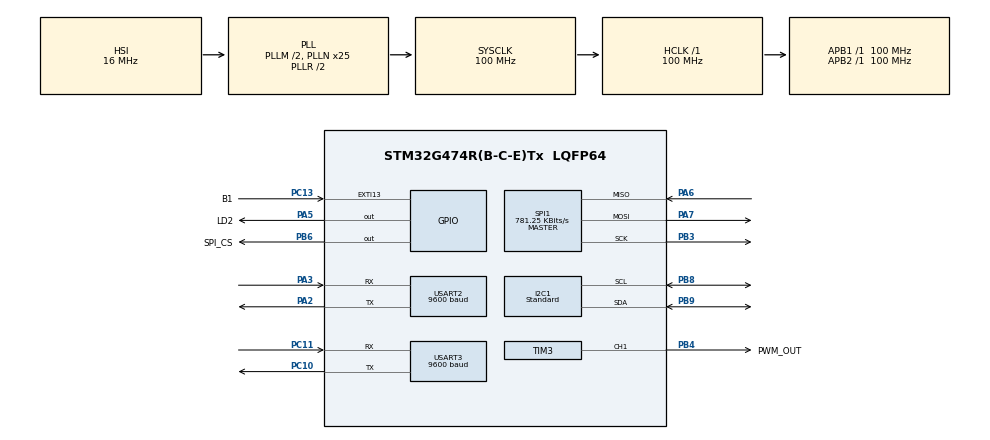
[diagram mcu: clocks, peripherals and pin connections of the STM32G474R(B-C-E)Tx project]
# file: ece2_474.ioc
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I2C1.AddressingMode=I2C_ADDRESSINGMODE_7BIT
I2C1.Analog_Filter=I2C_ANALOGFILTER_ENABLE
I2C1.CustomTiming=Disabled
I2C1.DualAddressMode=I2C_DUALADDRESS_DISABLE
I2C1.GeneralCallMode=I2C_GENERALCALL_DISABLE
I2C1.I2C_Coeff_DF=0
I2C1.I2C_Fall_Time=10
I2C1.I2C_Rise_Time=100
I2C1.I2C_Speed_Mode=I2C_Standard
I2C1.NoStretchMode=I2C_NOSTRETCH_DISABLE
I2C1.OwnAddress=0
I2C1.Speed=100
Mcu.Family=STM32G4
Mcu.Name=STM32G474R(B-C-E)Tx
Mcu.Package=LQFP64
NVIC.EXTI15_10_IRQn=true\:7\:0\:false\:false\:true\:true\:true\:true
NVIC.PriorityGroup=NVIC_PRIORITYGROUP_4
NVIC.TIM6_DAC_IRQn=true\:4\:0\:false\:false\:true\:true\:true\:true
NVIC.USART2_IRQn=true\:6\:0\:false\:false\:true\:true\:true\:true
NVIC.USART3_IRQn=true\:5\:0\:false\:false\:true\:true\:true\:true
PA13.Mode=Serial_Wire
PA13.Signal=SYS_JTMS-SWDIO
PA14.Mode=Serial_Wire
PA14.Signal=SYS_JTCK-SWCLK
PA2.Mode=Asynchronous
PA2.Signal=USART2_TX
PA3.Mode=Asynchronous
PA3.Signal=USART2_RX
PA5.GPIO_Label=LD2
PA5.PinState=GPIO_PIN_RESET
PA5.Signal=GPIO_Output
PA6.Mode=Full_Duplex_Master
PA6.Signal=SPI1_MISO
PA7.Mode=Full_Duplex_Master
PA7.Signal=SPI1_MOSI
PB3.Mode=Full_Duplex_Master
PB3.Signal=SPI1_SCK
PB4.GPIO_Label=PWM_OUT
PB4.Signal=S_TIM3_CH1
PB6.GPIO_Label=SPI_CS
PB6.PinState=GPIO_PIN_SET
PB6.Signal=GPIO_Output
PB8-BOOT0.Mode=I2C
PB8-BOOT0.Signal=I2C1_SCL
PB9.Mode=I2C
PB9.Signal=I2C1_SDA
PC10.Mode=Asynchronous
PC10.Signal=USART3_TX
PC11.Mode=Asynchronous
PC11.Signal=USART3_RX
PC13.GPIO_Label=B1
PC13.GPIO_ModeDefaultEXTI=GPIO_MODE_IT_RISING
PC13.GPIO_PuPd=GPIO_NOPULL
PC13.Signal=GPXTI13
ProjectManager.HeapSize=0x200
ProjectManager.StackSize=0x400
ProjectManager.TargetToolchain=CMake
RCC.ADC12Freq_Value=100000000
RCC.ADC345Freq_Value=100000000
RCC.AHBFreq_Value=100000000
RCC.APB1Freq_Value=100000000
RCC.APB1TimFreq_Value=100000000
RCC.APB2Freq_Value=100000000
RCC.APB2TimFreq_Value=100000000
RCC.CortexFreq_Value=100000000
RCC.EXTERNAL_CLOCK_VALUE=12288000
RCC.HCLKFreq_Value=100000000
RCC.HSE_VALUE=8000000
RCC.HSI48_VALUE=48000000
RCC.HSI_VALUE=16000000
RCC.LSE_VALUE=32768
RCC.PLLM=RCC_PLLM_DIV2
RCC.PLLN=25
RCC.SYSCLKFreq_VALUE=100000000
RCC.SYSCLKSource=RCC_SYSCLKSOURCE_PLLCLK
RCC.USBFreq_Value=100000000
RCC.VCOOutputFreq_Value=200000000
SH.S_TIM3_CH1.0=TIM3_CH1,PWM Generation1 CH1
SPI1.BaudRatePrescaler=SPI_BAUDRATEPRESCALER_128
SPI1.CLKPhase=SPI_PHASE_1EDGE
SPI1.CLKPolarity=SPI_POLARITY_LOW
SPI1.CRCCalculation=SPI_CRCCALCULATION_DISABLE
SPI1.CalculateBaudRate=781.25 KBits/s
SPI1.DataSize=SPI_DATASIZE_8BIT
SPI1.Direction=SPI_DIRECTION_2LINES
SPI1.FirstBit=SPI_FIRSTBIT_MSB
SPI1.Mode=SPI_MODE_MASTER
SPI1.NSS=SPI_NSS_SOFT
SPI1.NSSPMode=SPI_NSS_PULSE_DISABLE
SPI1.TIMode=SPI_TIMODE_DISABLE
SPI1.VirtualType=VM_MASTER
TIM3.AutoReloadPreload=TIM_AUTORELOAD_PRELOAD_DISABLE
TIM3.Channel-PWM\ Generation1\ CH1=TIM_CHANNEL_1
TIM3.ClockDivision=TIM_CLOCKDIVISION_DIV1
TIM3.CounterMode=TIM_COUNTERMODE_UP
TIM3.Dithering=Disable
TIM3.OCFastMode_PWM-PWM\ Generation1\ CH1=TIM_OCFAST_DISABLE
TIM3.OCMode_PWM-PWM\ Generation1\ CH1=TIM_OCMODE_PWM1
TIM3.OCPolarity_1=TIM_OCPOLARITY_HIGH
TIM3.PeriodNoDither=999
TIM3.Prescaler=99
TIM3.PulseNoDither_1=500
TIM3.TIM_MasterOutputTrigger=TIM_TRGO_RESET
TIM3.TIM_MasterSlaveMode=TIM_MASTERSLAVEMODE_DISABLE
TIM6.AutoReloadPreload=TIM_AUTORELOAD_PRELOAD_DISABLE
TIM6.CounterMode=TIM_COUNTERMODE_UP
TIM6.Dithering=Disable
TIM6.PeriodNoDither=999
TIM6.Prescaler=9999
TIM6.TIM_MasterOutputTrigger=TIM_TRGO_RESET
USART2.BaudRate=9600
USART2.Mode=MODE_TX_RX
USART2.OverSampling=UART_OVERSAMPLING_16
USART2.Parity=PARITY_NONE
USART2.StopBits=STOPBITS_1
USART2.VirtualMode-Asynchronous=VM_ASYNC
USART2.WordLength=WORDLENGTH_8B
USART3.BaudRate=9600
USART3.Mode=MODE_TX_RX
USART3.OverSampling=UART_OVERSAMPLING_16
USART3.Parity=PARITY_NONE
USART3.StopBits=STOPBITS_1
USART3.VirtualMode-Asynchronous=VM_ASYNC
USART3.WordLength=WORDLENGTH_8B
VP_SYS_VS_DBSignals.Mode=DisableDeadBatterySignals
VP_TIM3_VS_ClockSourceINT.Mode=Internal
VP_TIM6_VS_ClockSourceINT.Mode=Enable_Timer
board=NUCLEO-G474RE

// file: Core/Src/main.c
/* USER CODE BEGIN Header */
/**
  ******************************************************************************
  * @file           : main.c
  * @brief          : Main program body
  ******************************************************************************
  * @attention
  *
  * Copyright (c) 2026 STMicroelectronics.
  * All rights reserved.
  *
  * This software is licensed under terms that can be found in the LICENSE file
  * in the root directory of this software component.
  * If no LICENSE file comes with this software, it is provided AS-IS.
  *
  ******************************************************************************
  */
/* USER CODE END Header */
#include "main.h"

/* USER CODE BEGIN Includes */
#include "ece2_474.h"
/* USER CODE END Includes */

I2C_HandleTypeDef hi2c1;

SPI_HandleTypeDef hspi1;

TIM_HandleTypeDef htim3;
TIM_HandleTypeDef htim6;

UART_HandleTypeDef huart2;
UART_HandleTypeDef huart3;

void SystemClock_Config(void);
static void MX_GPIO_Init(void);
static void MX_USART2_UART_Init(void);
static void MX_SPI1_Init(void);
static void MX_I2C1_Init(void);
static void MX_TIM6_Init(void);
static void MX_TIM3_Init(void);
static void MX_USART3_UART_Init(void);

int main(void)
{

  /* MCU Configuration--------------------------------------------------------*/

  /* Reset of all peripherals, Initializes the Flash interface and the Systick. */
  HAL_Init();

  /* Configure the system clock */
  SystemClock_Config();

  /* Initialize all configured peripherals */
  MX_GPIO_Init();
  MX_USART2_UART_Init();
  MX_SPI1_Init();
  MX_I2C1_Init();
  MX_TIM6_Init();
  MX_TIM3_Init();
  MX_USART3_UART_Init();
  /* USER CODE BEGIN 2 */
  printf("Hello, World!\n");
  /* USER CODE END 2 */

  /* Infinite loop */
  while (1)
  {
    /* USER CODE BEGIN 3 */
    polling_routine();
  }

  /* USER CODE END 3 */
}

void SystemClock_Config(void)
{
  RCC_OscInitTypeDef RCC_OscInitStruct = {0};
  RCC_ClkInitTypeDef RCC_ClkInitStruct = {0};

  /** Configure the main internal regulator output voltage
  */
  HAL_PWREx_ControlVoltageScaling(PWR_REGULATOR_VOLTAGE_SCALE1);

  /** Initializes the RCC Oscillators according to the specified parameters
  * in the RCC_OscInitTypeDef structure.
  */
  RCC_OscInitStruct.OscillatorType = RCC_OSCILLATORTYPE_HSI;
  RCC_OscInitStruct.HSIState = RCC_HSI_ON;
  RCC_OscInitStruct.HSICalibrationValue = RCC_HSICALIBRATION_DEFAULT;
  RCC_OscInitStruct.PLL.PLLState = RCC_PLL_ON;
  RCC_OscInitStruct.PLL.PLLSource = RCC_PLLSOURCE_HSI;
  RCC_OscInitStruct.PLL.PLLM = RCC_PLLM_DIV2;
  RCC_OscInitStruct.PLL.PLLN = 25;
  RCC_OscInitStruct.PLL.PLLP = RCC_PLLP_DIV2;
  RCC_OscInitStruct.PLL.PLLQ = RCC_PLLQ_DIV2;
  RCC_OscInitStruct.PLL.PLLR = RCC_PLLR_DIV2;
  if (HAL_RCC_OscConfig(&RCC_OscInitStruct) != HAL_OK)
  {
    Error_Handler();
  }

  /** Initializes the CPU, AHB and APB buses clocks
  */
  RCC_ClkInitStruct.ClockType = RCC_CLOCKTYPE_HCLK|RCC_CLOCKTYPE_SYSCLK
                              |RCC_CLOCKTYPE_PCLK1|RCC_CLOCKTYPE_PCLK2;
  RCC_ClkInitStruct.SYSCLKSource = RCC_SYSCLKSOURCE_PLLCLK;
  RCC_ClkInitStruct.AHBCLKDivider = RCC_SYSCLK_DIV1;
  RCC_ClkInitStruct.APB1CLKDivider = RCC_HCLK_DIV1;
  RCC_ClkInitStruct.APB2CLKDivider = RCC_HCLK_DIV1;

  if (HAL_RCC_ClockConfig(&RCC_ClkInitStruct, FLASH_LATENCY_3) != HAL_OK)
  {
    Error_Handler();
  }
}

static void MX_I2C1_Init(void)
{

  hi2c1.Instance = I2C1;
  hi2c1.Init.Timing = 0x00303D5B;
  hi2c1.Init.OwnAddress1 = 0;
  hi2c1.Init.AddressingMode = I2C_ADDRESSINGMODE_7BIT;
  hi2c1.Init.DualAddressMode = I2C_DUALADDRESS_DISABLE;
  hi2c1.Init.OwnAddress2 = 0;
  hi2c1.Init.OwnAddress2Masks = I2C_OA2_NOMASK;
  hi2c1.Init.GeneralCallMode = I2C_GENERALCALL_DISABLE;
  hi2c1.Init.NoStretchMode = I2C_NOSTRETCH_DISABLE;
  if (HAL_I2C_Init(&hi2c1) != HAL_OK)
  {
    Error_Handler();
  }

  /** Configure Analogue filter
  */
  if (HAL_I2CEx_ConfigAnalogFilter(&hi2c1, I2C_ANALOGFILTER_ENABLE) != HAL_OK)
  {
    Error_Handler();
  }

  /** Configure Digital filter
  */
  if (HAL_I2CEx_ConfigDigitalFilter(&hi2c1, 0) != HAL_OK)
  {
    Error_Handler();
  }

}

static void MX_SPI1_Init(void)
{

  /* SPI1 parameter configuration*/
  hspi1.Instance = SPI1;
  hspi1.Init.Mode = SPI_MODE_MASTER;
  hspi1.Init.Direction = SPI_DIRECTION_2LINES;
  hspi1.Init.DataSize = SPI_DATASIZE_8BIT;
  hspi1.Init.CLKPolarity = SPI_POLARITY_LOW;
  hspi1.Init.CLKPhase = SPI_PHASE_1EDGE;
  hspi1.Init.NSS = SPI_NSS_SOFT;
  hspi1.Init.BaudRatePrescaler = SPI_BAUDRATEPRESCALER_128;
  hspi1.Init.FirstBit = SPI_FIRSTBIT_MSB;
  hspi1.Init.TIMode = SPI_TIMODE_DISABLE;
  hspi1.Init.CRCCalculation = SPI_CRCCALCULATION_DISABLE;
  hspi1.Init.CRCPolynomial = 7;
  hspi1.Init.CRCLength = SPI_CRC_LENGTH_DATASIZE;
  hspi1.Init.NSSPMode = SPI_NSS_PULSE_DISABLE;
  if (HAL_SPI_Init(&hspi1) != HAL_OK)
  {
    Error_Handler();
  }

}

static void MX_TIM3_Init(void)
{

  TIM_ClockConfigTypeDef sClockSourceConfig = {0};
  TIM_MasterConfigTypeDef sMasterConfig = {0};
  TIM_OC_InitTypeDef sConfigOC = {0};

  htim3.Instance = TIM3;
  htim3.Init.Prescaler = 99;
  htim3.Init.CounterMode = TIM_COUNTERMODE_UP;
  htim3.Init.Period = 999;
  htim3.Init.ClockDivision = TIM_CLOCKDIVISION_DIV1;
  htim3.Init.AutoReloadPreload = TIM_AUTORELOAD_PRELOAD_DISABLE;
  if (HAL_TIM_Base_Init(&htim3) != HAL_OK)
  {
    Error_Handler();
  }
  sClockSourceConfig.ClockSource = TIM_CLOCKSOURCE_INTERNAL;
  if (HAL_TIM_ConfigClockSource(&htim3, &sClockSourceConfig) != HAL_OK)
  {
    Error_Handler();
  }
  if (HAL_TIM_PWM_Init(&htim3) != HAL_OK)
  {
    Error_Handler();
  }
  sMasterConfig.MasterOutputTrigger = TIM_TRGO_RESET;
  sMasterConfig.MasterSlaveMode = TIM_MASTERSLAVEMODE_DISABLE;
  if (HAL_TIMEx_MasterConfigSynchronization(&htim3, &sMasterConfig) != HAL_OK)
  {
    Error_Handler();
  }
  sConfigOC.OCMode = TIM_OCMODE_PWM1;
  sConfigOC.Pulse = 500;
  sConfigOC.OCPolarity = TIM_OCPOLARITY_HIGH;
  sConfigOC.OCFastMode = TIM_OCFAST_DISABLE;
  if (HAL_TIM_PWM_ConfigChannel(&htim3, &sConfigOC, TIM_CHANNEL_1) != HAL_OK)
  {
    Error_Handler();
  }
  HAL_TIM_MspPostInit(&htim3);

}

static void MX_TIM6_Init(void)
{

  TIM_MasterConfigTypeDef sMasterConfig = {0};

  htim6.Instance = TIM6;
  htim6.Init.Prescaler = 9999;
  htim6.Init.CounterMode = TIM_COUNTERMODE_UP;
  htim6.Init.Period = 999;
  htim6.Init.AutoReloadPreload = TIM_AUTORELOAD_PRELOAD_DISABLE;
  if (HAL_TIM_Base_Init(&htim6) != HAL_OK)
  {
    Error_Handler();
  }
  sMasterConfig.MasterOutputTrigger = TIM_TRGO_RESET;
  sMasterConfig.MasterSlaveMode = TIM_MASTERSLAVEMODE_DISABLE;
  if (HAL_TIMEx_MasterConfigSynchronization(&htim6, &sMasterConfig) != HAL_OK)
  {
    Error_Handler();
  }

}

static void MX_USART2_UART_Init(void)
{

  huart2.Instance = USART2;
  huart2.Init.BaudRate = 9600;
  huart2.Init.WordLength = UART_WORDLENGTH_8B;
  huart2.Init.StopBits = UART_STOPBITS_1;
  huart2.Init.Parity = UART_PARITY_NONE;
  huart2.Init.Mode = UART_MODE_TX_RX;
  huart2.Init.HwFlowCtl = UART_HWCONTROL_NONE;
  huart2.Init.OverSampling = UART_OVERSAMPLING_16;
  huart2.Init.OneBitSampling = UART_ONE_BIT_SAMPLE_DISABLE;
  huart2.Init.ClockPrescaler = UART_PRESCALER_DIV1;
  huart2.AdvancedInit.AdvFeatureInit = UART_ADVFEATURE_NO_INIT;
  if (HAL_UART_Init(&huart2) != HAL_OK)
  {
    Error_Handler();
  }
  if (HAL_UARTEx_SetTxFifoThreshold(&huart2, UART_TXFIFO_THRESHOLD_1_8) != HAL_OK)
  {
    Error_Handler();
  }
  if (HAL_UARTEx_SetRxFifoThreshold(&huart2, UART_RXFIFO_THRESHOLD_1_8) != HAL_OK)
  {
    Error_Handler();
  }
  if (HAL_UARTEx_DisableFifoMode(&huart2) != HAL_OK)
  {
    Error_Handler();
  }

}

static void MX_USART3_UART_Init(void)
{

  huart3.Instance = USART3;
  huart3.Init.BaudRate = 9600;
  huart3.Init.WordLength = UART_WORDLENGTH_8B;
  huart3.Init.StopBits = UART_STOPBITS_1;
  huart3.Init.Parity = UART_PARITY_NONE;
  huart3.Init.Mode = UART_MODE_TX_RX;
  huart3.Init.HwFlowCtl = UART_HWCONTROL_NONE;
  huart3.Init.OverSampling = UART_OVERSAMPLING_16;
  huart3.Init.OneBitSampling = UART_ONE_BIT_SAMPLE_DISABLE;
  huart3.Init.ClockPrescaler = UART_PRESCALER_DIV1;
  huart3.AdvancedInit.AdvFeatureInit = UART_ADVFEATURE_NO_INIT;
  if (HAL_UART_Init(&huart3) != HAL_OK)
  {
    Error_Handler();
  }
  if (HAL_UARTEx_SetTxFifoThreshold(&huart3, UART_TXFIFO_THRESHOLD_1_8) != HAL_OK)
  {
    Error_Handler();
  }
  if (HAL_UARTEx_SetRxFifoThreshold(&huart3, UART_RXFIFO_THRESHOLD_1_8) != HAL_OK)
  {
    Error_Handler();
  }
  if (HAL_UARTEx_DisableFifoMode(&huart3) != HAL_OK)
  {
    Error_Handler();
  }

}

static void MX_GPIO_Init(void)
{
  GPIO_InitTypeDef GPIO_InitStruct = {0};

  /* GPIO Ports Clock Enable */
  __HAL_RCC_GPIOC_CLK_ENABLE();
  __HAL_RCC_GPIOA_CLK_ENABLE();
  __HAL_RCC_GPIOB_CLK_ENABLE();

  /*Configure GPIO pin Output Level */
  HAL_GPIO_WritePin(LD2_GPIO_Port, LD2_Pin, GPIO_PIN_RESET);

  /*Configure GPIO pin Output Level */
  HAL_GPIO_WritePin(SPI_CS_GPIO_Port, SPI_CS_Pin, GPIO_PIN_SET);

  /*Configure GPIO pin : B1_Pin */
  GPIO_InitStruct.Pin = B1_Pin;
  GPIO_InitStruct.Mode = GPIO_MODE_IT_RISING;
  GPIO_InitStruct.Pull = GPIO_NOPULL;
  HAL_GPIO_Init(B1_GPIO_Port, &GPIO_InitStruct);

  /*Configure GPIO pin : LD2_Pin */
  GPIO_InitStruct.Pin = LD2_Pin;
  GPIO_InitStruct.Mode = GPIO_MODE_OUTPUT_PP;
  GPIO_InitStruct.Pull = GPIO_NOPULL;
  GPIO_InitStruct.Speed = GPIO_SPEED_FREQ_LOW;
  HAL_GPIO_Init(LD2_GPIO_Port, &GPIO_InitStruct);

  /*Configure GPIO pin : SPI_CS_Pin */
  GPIO_InitStruct.Pin = SPI_CS_Pin;
  GPIO_InitStruct.Mode = GPIO_MODE_OUTPUT_PP;
  GPIO_InitStruct.Pull = GPIO_NOPULL;
  GPIO_InitStruct.Speed = GPIO_SPEED_FREQ_LOW;
  HAL_GPIO_Init(SPI_CS_GPIO_Port, &GPIO_InitStruct);

  /* EXTI interrupt init*/
  HAL_NVIC_SetPriority(EXTI15_10_IRQn, 7, 0);
  HAL_NVIC_EnableIRQ(EXTI15_10_IRQn);

}

void Error_Handler(void)
{
  __disable_irq();
  while (1)
  {
  }
}
